# nrf52 register map
Vendor: Nordic Semiconductor; Series: nrf52; File version: 1
CPU: CM4 r0p1, little endian, MPU, FPU, 3 interrupt priority bits
Registers are 32-bit, read-write, reset 0x0 unless marked. A register's access mark holds for its fields unless they carry their own. Offsets are from the block's base; [hi:lo] are bit positions; lines under a group give offsets from that group; {n}, {i} and the like mark numbered series; 'fields as' and 'values as' point back to an identical list.

## POWER — Power control
Base 0x40000000; alternate view of APPROTECT
0x78 TASKS_CONSTLAT wo — Enable constant latency mode
  [0] TASKS_CONSTLAT
    1=Trigger task
0x7C TASKS_LOWPWR wo — Enable low power mode (variable latency)
  [0] TASKS_LOWPWR
    1=Trigger task
0x108 EVENTS_POFWARN — Power failure warning
  [0] EVENTS_POFWARN
    0=NotGenerated (Event not generated); 1=Generated (Event generated)
0x114 EVENTS_SLEEPENTER — CPU entered WFI/WFE sleep
  [0] EVENTS_SLEEPENTER
    values as EVENTS_POFWARN.EVENTS_POFWARN
0x118 EVENTS_SLEEPEXIT — CPU exited WFI/WFE sleep
  [0] EVENTS_SLEEPEXIT
    values as EVENTS_POFWARN.EVENTS_POFWARN
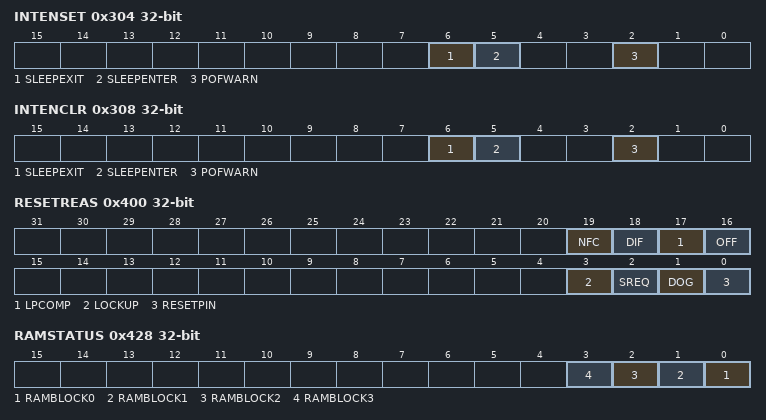
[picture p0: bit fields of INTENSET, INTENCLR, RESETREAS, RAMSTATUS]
0x304 INTENSET — Enable interrupt
  [all] fields
    on read: 0=Disabled (Read: Disabled); 1=Enabled (Read: Enabled) | on write: 1=Set (Enable)
  [6] SLEEPEXIT — Write '1' to enable interrupt for event SLEEPEXIT
  [5] SLEEPENTER — Write '1' to enable interrupt for event SLEEPENTER
  [2] POFWARN — Write '1' to enable interrupt for event POFWARN
0x308 INTENCLR — Disable interrupt
  [all] fields
    on read: 0=Disabled (Read: Disabled); 1=Enabled (Read: Enabled) | on write: 1=Clear (Disable)
  [6] SLEEPEXIT — Write '1' to disable interrupt for event SLEEPEXIT
  [5] SLEEPENTER — Write '1' to disable interrupt for event SLEEPENTER
  [2] POFWARN — Write '1' to disable interrupt for event POFWARN
0x400 RESETREAS — Reset reason
  [all] fields
    0=NotDetected; 1=Detected
  [19] NFC — Reset due to wake up from System OFF mode by NFC field detect
  [18] DIF — Reset due to wake up from System OFF mode when wakeup is triggered from entering into debug interface mode
  [17] LPCOMP — Reset due to wake up from System OFF mode when wakeup is triggered from ANADETECT signal from LPCOMP
  [16] OFF — Reset due to wake up from System OFF mode when wakeup is triggered from DETECT signal from GPIO
  [3] LOCKUP — Reset from CPU lock-up detected
  [2] SREQ — Reset from soft reset detected
  [1] DOG — Reset from watchdog detected
  [0] RESETPIN — Reset from pin-reset detected
0x428 RAMSTATUS ro — Deprecated register - RAM status register
  [all] fields
    0=Off; 1=On
  [n] RAMBLOCK{n} (n=0..3) — RAM block {n} is on or off/powering up
0x500 SYSTEMOFF wo
  [0] SYSTEMOFF — Enable System OFF mode
    1=Enter (Enable System OFF mode)
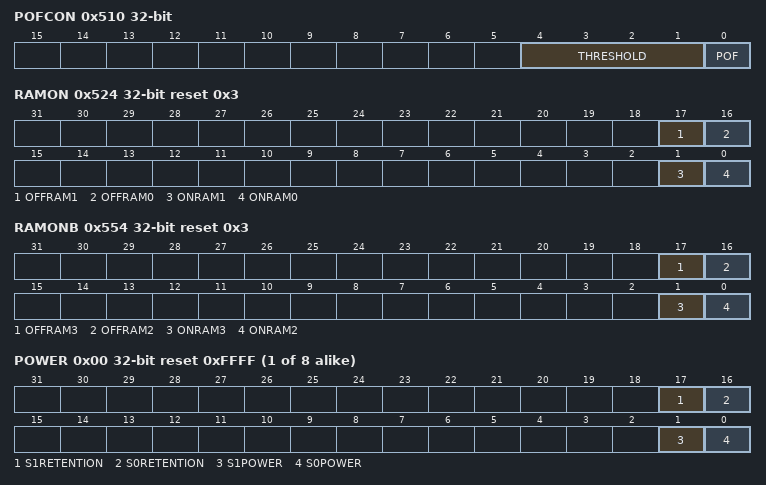
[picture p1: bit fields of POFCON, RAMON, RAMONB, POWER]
0x510 POFCON — Power failure comparator configuration
  [4:1] THRESHOLD — Power failure comparator threshold setting
    4=V17 (Set threshold to 1.7 V); 5=V18 (Set threshold to 1.8 V); 6=V19 (Set threshold to 1.9 V); 7=V20 (Set threshold to 2.0 V); 8=V21 (Set threshold to 2.1 V); 9=V22 (Set threshold to 2.2 V); 10=V23 (Set threshold to 2.3 V); 11=V24 (Set threshold to 2.4 V); 12=V25 (Set threshold to 2.5 V); 13=V26 (Set threshold to 2.6 V); 14=V27 (Set threshold to 2.7 V); 15=V28 (Set threshold to 2.8 V)
  [0] POF — Enable or disable power failure comparator
    0=Disabled; 1=Enabled
0x51C GPREGRET — General purpose retention register
  [7:0] GPREGRET
0x520 GPREGRET2 — General purpose retention register
  [7:0] GPREGRET
0x524 RAMON reset 0x3 — Deprecated register - RAM on/off register (this register is retained)
  [17] OFFRAM1 — Keep retention on RAM block 1 when RAM block is switched off
    0=RAM1Off (Off); 1=RAM1On (On)
  [16] OFFRAM0 — Keep retention on RAM block 0 when RAM block is switched off
    0=RAM0Off (Off); 1=RAM0On (On)
  [1] ONRAM1 — Keep RAM block 1 on or off in system ON Mode
    0=RAM1Off (Off); 1=RAM1On (On)
  [0] ONRAM0 — Keep RAM block 0 on or off in system ON Mode
    0=RAM0Off (Off); 1=RAM0On (On)
0x554 RAMONB reset 0x3 — Deprecated register - RAM on/off register (this register is retained)
  [17] OFFRAM3 — Keep retention on RAM block 3 when RAM block is switched off
    0=RAM3Off (Off); 1=RAM3On (On)
  [16] OFFRAM2 — Keep retention on RAM block 2 when RAM block is switched off
    0=RAM2Off (Off); 1=RAM2On (On)
  [1] ONRAM3 — Keep RAM block 3 on or off in system ON Mode
    0=RAM3Off (Off); 1=RAM3On (On)
  [0] ONRAM2 — Keep RAM block 2 on or off in system ON Mode
    0=RAM2Off (Off); 1=RAM2On (On)
0x578 DCDCEN — DC/DC enable register
  [0] DCDCEN — Enable or disable DC/DC converter
    0=Disabled; 1=Enabled
{0x900+0x10*i} RAM[{i}] (i=0..7) group — Unspecified
  0x00 POWER reset 0xFFFF — Description cluster: RAMn power control register
    [all] fields
      0=Off; 1=On
    [17] S1RETENTION — Keep retention on RAM section S1 when RAM section is in OFF
    [16] S0RETENTION — Keep retention on RAM section S0 when RAM section is in OFF
    [1] S1POWER — Keep RAM section S1 ON or OFF in System ON mode.
    [0] S0POWER — Keep RAM section S0 ON or OFF in System ON mode.
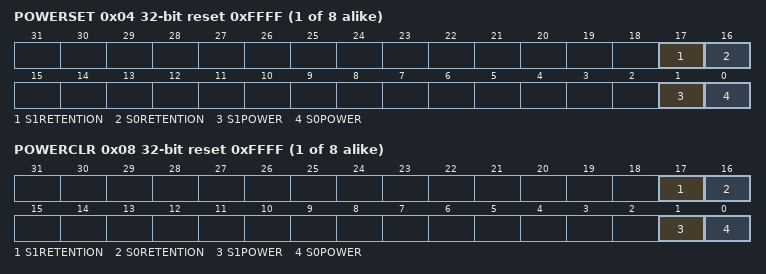
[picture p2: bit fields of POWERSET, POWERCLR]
  0x04 POWERSET wo reset 0xFFFF — Description cluster: RAMn power control set register
    [all] fields
      1=On
    [17] S1RETENTION — Keep retention on RAM section S1 when RAM section is switched off
    [16] S0RETENTION — Keep retention on RAM section S0 when RAM section is switched off
    [1] S1POWER — Keep RAM section S1 of RAMn on or off in System ON mode
    [0] S0POWER — Keep RAM section S0 of RAMn on or off in System ON mode
  0x08 POWERCLR wo reset 0xFFFF — Description cluster: RAMn power control clear register
    [all] fields
      1=Off
    [17] S1RETENTION — Keep retention on RAM section S1 when RAM section is switched off
    [16] S0RETENTION — Keep retention on RAM section S0 when RAM section is switched off
    [1] S1POWER — Keep RAM section S1 of RAMn on or off in System ON mode
    [0] S0POWER — Keep RAM section S0 of RAMn on or off in System ON mode
